# headsail register map
Vendor: tuni.fi; File version: 1.0
CPU: other r1p0, little endian, no MPU, no FPU, vendor SysTick, 2 interrupt priority bits
Registers are 32-bit, read-write, no defined reset value unless marked. A register's access mark holds for its fields unless they carry their own. Offsets are from the block's base; lines under a group give offsets from that group; [hi:lo] are bit positions; {n}, {i} and the like mark numbered series; 'fields as' and 'values as' point back to an identical list; <NAME> marks a mode.

## Memory map
0x00000000 sdram
0x00101000 SYSCTRL blocks up to offset 0x20000
0x70080000 C2C_parallel
0x80080000 C2C_serial
0x90080000 ram
0x90280000 ram
0x90480000 ram
0x90680000 ram
0xFF600000 confReg size 0x44
0xFF600200 mdio_map0 size 0x1C
0xFF600400 mdio_map1 size 0x1C
0xFFA00000 DMA0 blocks up to offset 0x240 — The Excel of Register Map can be found here. https://tuni.sharepoint.com/:x:/r/sites/TG-SoC-Hub/_layouts/15/Doc.aspx?sourcedoc=%7B971A5DEF-758E-4A18-8EA3-0F3F2D60F0BB%7D&file=DMA_register_map.xlsx&action=default&mobileredirect=true&cid=419a13fc-9dbd-45b9-8f31-77899c555ace DMA Sub System Document available in below link: https://tuni.sharepoint.com/:w:/r/sites/TG-SoC-Hub/_layouts/15/Doc.aspx?sourcedoc=%7B9E9DFD0D-B0CA-436B-ABA0-57DB3B73560E%7D&file=DMA_Sub_System_Document.....docx&action=default&mobileredirect=true
0xFFA08000 DMA1 blocks up to offset 0x240 — The Excel of Register Map can be found here. https://tuni.sharepoint.com/:x:/r/sites/TG-SoC-Hub/_layouts/15/Doc.aspx?sourcedoc=%7B971A5DEF-758E-4A18-8EA3-0F3F2D60F0BB%7D&file=DMA_register_map.xlsx&action=default&mobileredirect=true&cid=419a13fc-9dbd-45b9-8f31-77899c555ace DMA Sub System Document available in below link: https://tuni.sharepoint.com/:w:/r/sites/TG-SoC-Hub/_layouts/15/Doc.aspx?sourcedoc=%7B9E9DFD0D-B0CA-436B-ABA0-57DB3B73560E%7D&file=DMA_Sub_System_Document.....docx&action=default&mobileredirect=true
0xFFB00000 C2C_config size 0x40
0xFFC00000 C2C_serial_config size 0x5C
0xFFD00000 sdram_cfg size 0x74
0xFFF00000 uart0 size 0x8
0xFFF01000 uart1 size 0x8
0xFFF02000 spi_master0 size 0x2C
0xFFF03000 spi_master1 size 0x2C
0xFFF05000 i2c size 0x18

## confReg
Base 0xFF600000
0x00 padCfg group
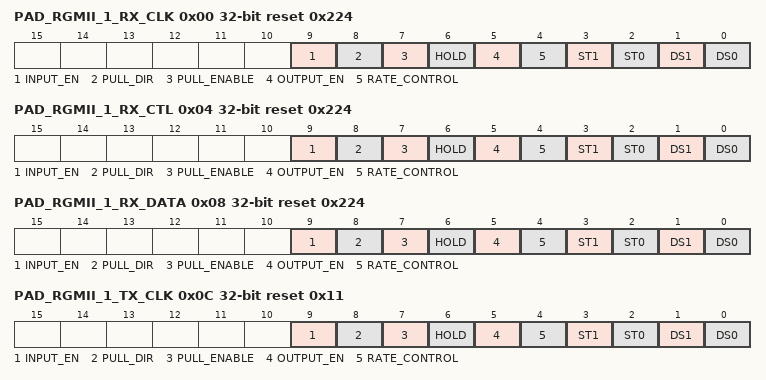
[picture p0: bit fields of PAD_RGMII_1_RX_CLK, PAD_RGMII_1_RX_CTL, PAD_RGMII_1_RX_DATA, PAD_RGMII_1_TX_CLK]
  0x00 PAD_RGMII_1_RX_CLK reset 0x224 (reset mask 0x0)
    [9] INPUT_EN
      1=enable_input; 0=disable_input
    [8] PULL_DIR
      1=pull_up; 0=pull_down
    [7] PULL_ENABLE
      1=enable_pull; 0=disable_pull
    [6] HOLD
      1=disable_pad; 0=enable_pad
    [5] OUTPUT_EN
      1=disable_output; 0=enable_output
    [4] RATE_CONTROL
      1=enable; 0=disable
    [3] ST1
      1=enable; 0=disable
    [2] ST0
      0=disable; 1=enable
    [1] DS1
      1=enable; 0=disable
    [0] DS0
      1=enable; 0=disable
  0x04 PAD_RGMII_1_RX_CTL reset 0x224 (reset mask 0x0)
    fields as padCfg.PAD_RGMII_1_RX_CLK
  0x08 PAD_RGMII_1_RX_DATA reset 0x224 (reset mask 0x0)
    fields as padCfg.PAD_RGMII_1_RX_CLK
  0x0C PAD_RGMII_1_TX_CLK reset 0x11 (reset mask 0x0)
    fields as padCfg.PAD_RGMII_1_RX_CLK
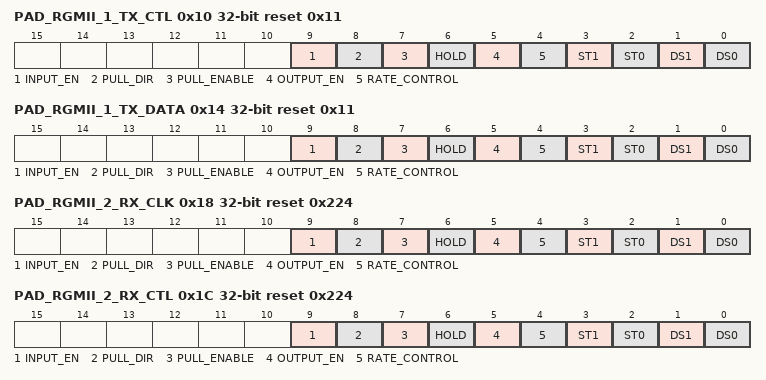
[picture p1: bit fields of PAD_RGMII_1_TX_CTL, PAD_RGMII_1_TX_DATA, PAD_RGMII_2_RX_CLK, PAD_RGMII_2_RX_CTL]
  0x10 PAD_RGMII_1_TX_CTL reset 0x11 (reset mask 0x0)
    fields as padCfg.PAD_RGMII_1_RX_CLK
  0x14 PAD_RGMII_1_TX_DATA reset 0x11 (reset mask 0x0)
    fields as padCfg.PAD_RGMII_1_RX_CLK
  0x18 PAD_RGMII_2_RX_CLK reset 0x224 (reset mask 0x0)
    fields as padCfg.PAD_RGMII_1_RX_CLK
  0x1C PAD_RGMII_2_RX_CTL reset 0x224 (reset mask 0x0)
    fields as padCfg.PAD_RGMII_1_RX_CLK
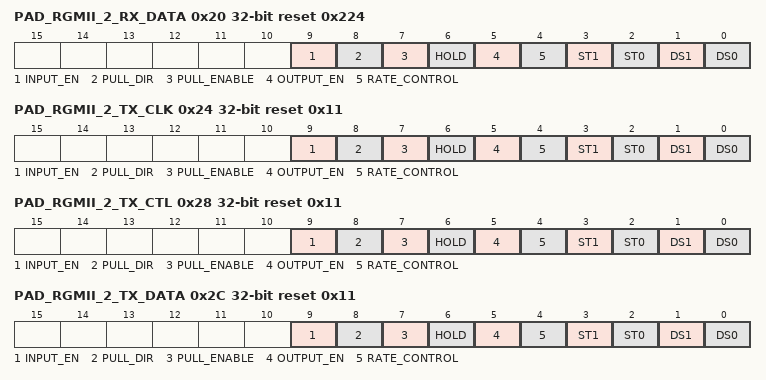
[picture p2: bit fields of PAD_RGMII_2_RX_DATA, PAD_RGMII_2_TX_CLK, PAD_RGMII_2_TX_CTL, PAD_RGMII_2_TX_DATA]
  0x20 PAD_RGMII_2_RX_DATA reset 0x224 (reset mask 0x0)
    fields as padCfg.PAD_RGMII_1_RX_CLK
  0x24 PAD_RGMII_2_TX_CLK reset 0x11 (reset mask 0x0)
    fields as padCfg.PAD_RGMII_1_RX_CLK
  0x28 PAD_RGMII_2_TX_CTL reset 0x11 (reset mask 0x0)
    fields as padCfg.PAD_RGMII_1_RX_CLK
  0x2C PAD_RGMII_2_TX_DATA reset 0x11 (reset mask 0x0)
    fields as padCfg.PAD_RGMII_1_RX_CLK
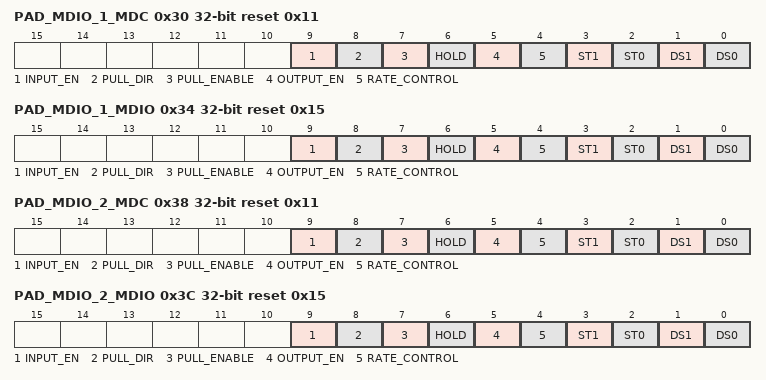
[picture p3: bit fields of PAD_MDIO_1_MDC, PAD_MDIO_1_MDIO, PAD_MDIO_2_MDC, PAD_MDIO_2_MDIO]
  0x30 PAD_MDIO_1_MDC reset 0x11 (reset mask 0x0)
    fields as padCfg.PAD_RGMII_1_RX_CLK
  0x34 PAD_MDIO_1_MDIO reset 0x15 (reset mask 0x0)
    [9] INPUT_EN ro
      1=enable_input; 0=disable_input
    [8] PULL_DIR
      1=pull_up; 0=pull_down
    [7] PULL_ENABLE
      1=enable_pull; 0=disable_pull
    [6] HOLD
      1=disable_pad; 0=enable_pad
    [5] OUTPUT_EN ro
      1=disable_output; 0=enable_output
    [4] RATE_CONTROL
      1=enable; 0=disable
    [3] ST1
      1=enable; 0=disable
    [2] ST0
      0=disable; 1=enable
    [1] DS1
      1=enable; 0=disable
    [0] DS0
      1=enable; 0=disable
  0x38 PAD_MDIO_2_MDC reset 0x11 (reset mask 0x0)
    fields as padCfg.PAD_RGMII_1_RX_CLK
  0x3C PAD_MDIO_2_MDIO reset 0x15 (reset mask 0x0)
    fields as padCfg.PAD_MDIO_1_MDIO
  0x40 RGMII_SEL
    [0] RGMII_SEL
      0=SEL_TSN_IP; 1=SEL_ETH_IP
